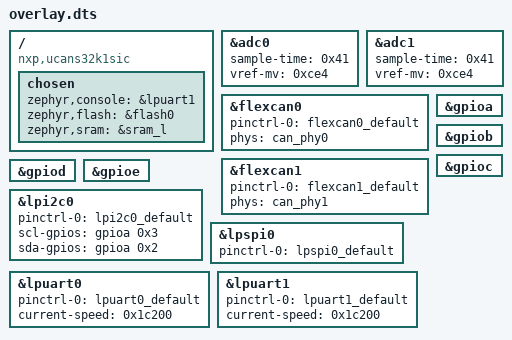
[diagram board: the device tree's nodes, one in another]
/ {
	compatible = "nxp,ucans32k1sic";
	chosen {
		zephyr,console = &lpuart1;
		zephyr,flash = &flash0;
		zephyr,sram = &sram_l;
	};
};
&adc0{
	status = "okay";
	sample-time = < 0x41 >;
	vref-mv = < 0xce4 >;
};
&adc1{
	status = "okay";
	sample-time = < 0x41 >;
	vref-mv = < 0xce4 >;
};
&flexcan0{
	status = "okay";
	pinctrl-0 = < &flexcan0_default >;
	pinctrl-names = "default";
	phys = < &can_phy0 >;
};
&flexcan1{
	status = "okay";
	pinctrl-0 = < &flexcan1_default >;
	pinctrl-names = "default";
	phys = < &can_phy1 >;
};
&gpioa{
	status = "okay";
};
&gpiob{
	status = "okay";
};
&gpioc{
	status = "okay";
};
&gpiod{
	status = "okay";
};
&gpioe{
	status = "okay";
};
&lpi2c0{
	status = "okay";
	pinctrl-0 = < &lpi2c0_default >;
	pinctrl-names = "default";
	scl-gpios = < &gpioa 0x3 0x0 >;
	sda-gpios = < &gpioa 0x2 0x0 >;
};
&lpspi0{
	status = "okay";
	pinctrl-0 = < &lpspi0_default >;
	pinctrl-names = "default";
};
&lpuart0{
	pinctrl-0 = < &lpuart0_default >;
	pinctrl-names = "default";
	current-speed = < 0x1c200 >;
};
&lpuart1{
	status = "okay";
	pinctrl-0 = < &lpuart1_default >;
	pinctrl-names = "default";
	current-speed = < 0x1c200 >;
};
